AUTOSAR XML (schema 00049)
package /Application/DltConfig
  dlt log channel to process mapping DltLogChannelToProcessMapping_LIT_TO_LIT: dlt-log-channel=LIT, process=LIT
package /Application/Executable
  executable LIT: category=APPLICATION_LEVEL, logging-behavior=USES-LOGGING, reporting-behavior=REPORTS-EXECUTION-STATE, version=1.0.0
    root sw component prototype AA: application-type=LIT
package /Application/Manifest
  service instance to port prototype mapping LIT_AA_RPortSoaDms: port-prototype=AA.RPortSoaDms, service-instance=Consumer_SoaDms
  service instance to port prototype mapping LIT_AA_RPortSoaSmartFilm: port-prototype=AA.RPortSoaSmartFilm, service-instance=Consumer_SoaSmartFilm
  service instance to port prototype mapping LIT_AA_RPortSubscriptionmanagement: port-prototype=AA.RPortSubscriptionmanagement, service-instance=EEVP_LIT_Consumer_SubscriptionManagement
package /Application/Process
  process LIT: executable=LIT, state-dependent-startup-config{function-group-state=[SFG07.On, SFG07.Verify], resource-group=DefaultResourceGroup, startup-config=DefaultStartupConfig}
    process state machine LIT: type=ProcessState
package /Application/SwComponent
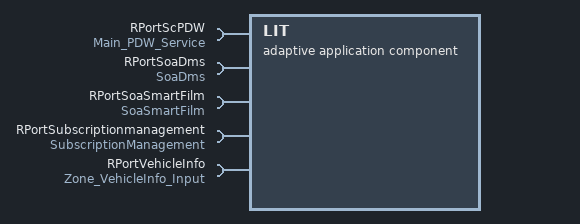
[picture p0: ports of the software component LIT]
  adaptive application sw component type LIT
    5 x require port:
      RPortScPDW: required-interface=Main_PDW_Service
      RPortSoaDms: required-interface=SoaDms
      RPortSoaSmartFilm: required-interface=SoaSmartFilm
      RPortSubscriptionmanagement: required-interface=SubscriptionManagement
      RPortVehicleInfo: required-interface=Zone_VehicleInfo_Input
